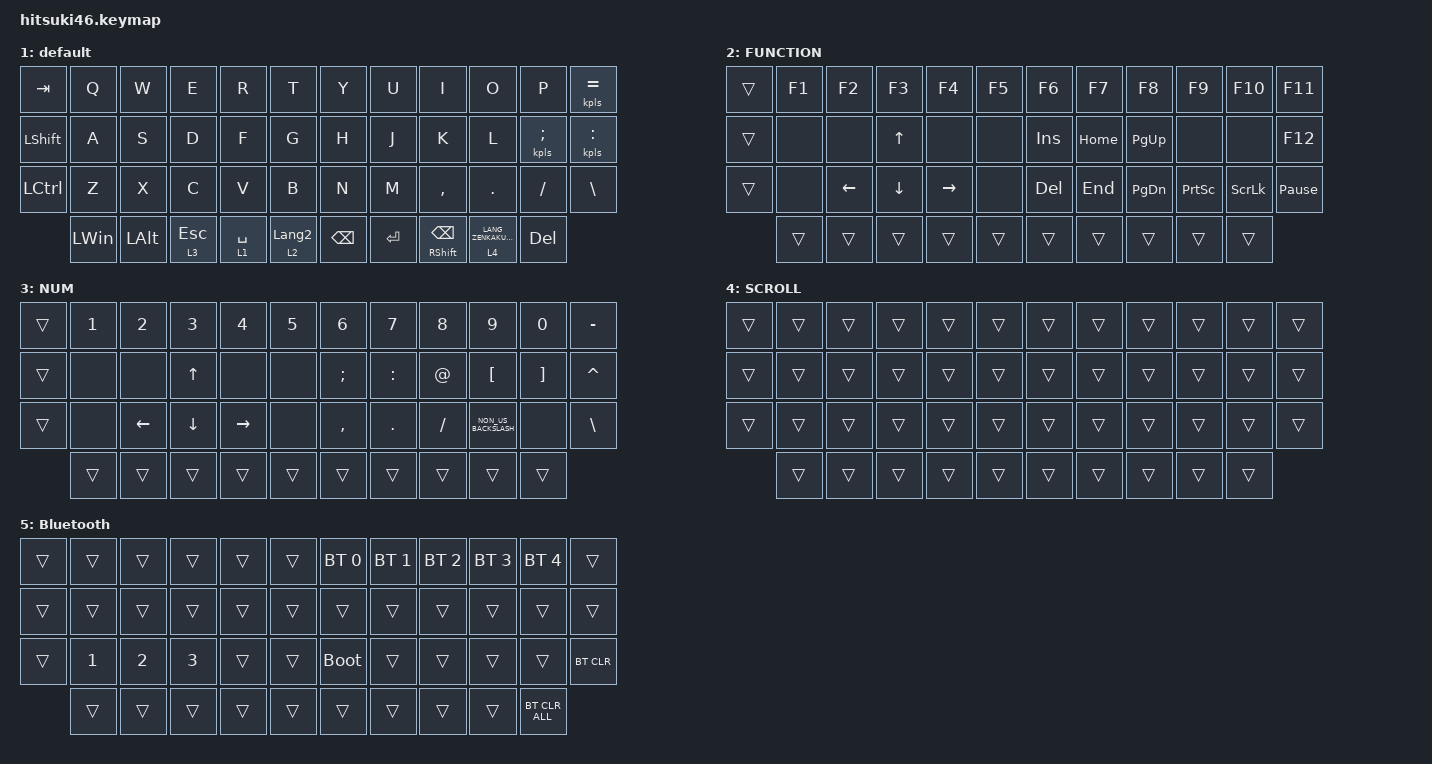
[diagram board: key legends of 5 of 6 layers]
#include <behaviors.dtsi>
#include <dt-bindings/zmk/bt.h>
#include <dt-bindings/zmk/keys.h>
#include <layout_shift_kp_override.dtsi>


/ {
    keymap {
        compatible = "zmk,keymap";

        default_layer {
            bindings = <
                &kpls EQUAL    // 通常は = を出力するが、JISレイアウトでは _ (JISレイアウトでの = に対応)を出力する
                &tog_ls        // レイアウトシフトのオン/オフを切り替える
                &tog_ls_on     // レイアウトシフトをオンにする
                &tog_ls_off    // レイアウトシフトをオフにする
            >;
        };
    };
};

/ {
    behaviors {
        // Keep the original key_press behavior for ZMK core components
        original_key_press: original_key_press {
            compatible = "zmk,behavior-key-press";
            #binding-cells = <1>;
            label = "KEY_PRESS";
        };

        // Override the existing &kp behavior to use our custom implementation
        kp: key_press {
            compatible = "zmk,behavior-layout-shift-key-press";
            #binding-cells = <1>;
            label = "LAYOUT_SHIFT_KEY_PRESS";
        };
    };
};

&mt {
    flavor = "balanced";
    quick-tap-ms = <0>;
};

// &trackball {
//     // Note: automouse-layer and scroll-layers are no longer supported in badjeff/zmk-pmw3610-driver
//     // These features should now be configured using layer-based zmk,input-listener in keymap
//     // automouse-layer = <1>;
//     // scroll-layers = <5>;
// };

/ {
    combos {
        compatible = "zmk,combos";

        tab {
            bindings = <&kp TAB>;
            key-positions = <11 12>;
        };

        shift_tab {
            bindings = <&kp LS(TAB)>;
            key-positions = <12 13>;
        };

        muhennkann {
            bindings = <&to_layer_0 INT_MUHENKAN>;
            key-positions = <11 10>;
        };

        double_quotation {
            bindings = <&kp DOUBLE_QUOTES>;
            key-positions = <20 21>;
        };

        eq {
            bindings = <&kp EQUAL>;
            key-positions = <24 25>;
        };
    };

    macros {
        to_layer_0: to_layer_0 {
            compatible = "zmk,behavior-macro-one-param";
            #binding-cells = <1>;
            bindings = <&to 0 &macro_param_1to1 &kp MACRO_PLACEHOLDER>;
            label = "TO_LAYER_0";
        };
    };

    behaviors {
        lt_to_layer_0: lt_to_layer_0 {
            compatible = "zmk,behavior-hold-tap";
            label = "LAYER_TAP_TO_0";
            bindings = <&mo>, <&to_layer_0>;

            #binding-cells = <2>;
            tapping-term-ms = <200>;
        };
    };

    keymap {
        compatible = "zmk,keymap";

        default {
            bindings = <
&kp TAB     &kp Q         &kp W         &kp E      &kp R        &kp T             &kp Y          &kp U      &kp I                 &kp O                      &kp P            &kpls EQUAL
&kp LSHIFT  &kp A         &kp S         &kp D      &kp F        &kp G             &kp H          &kp J      &kp K                 &kp L                      &kpls SEMICOLON  &kpls COLON
&kp LCTRL   &kp Z         &kp X         &kp C      &kp V        &kp B             &kp N          &kp M      &kp COMMA             &kp PERIOD                 &kp SLASH        &kp BACKSLASH
            &kp LEFT_WIN  &kp LEFT_ALT  &lt 3 ESC  &lt 1 SPACE  &lt 2 LANGUAGE_2  &kp BACKSPACE  &kp ENTER  &mt RSHIFT BACKSPACE  &lt 4 LANG_ZENKAKUHANKAKU  &kp DELETE
            >;
        };

        FUNCTION {
            bindings = <
&trans  &kp F1  &kp F2          &kp F3          &kp F4           &kp F5  &kp F6      &kp F7    &kp F8         &kp F9           &kp F10         &kp F11
&trans  &none   &none           &kp UP_ARROW    &none            &none   &kp INSERT  &kp HOME  &kp PAGE_UP    &none            &none           &kp F12
&trans  &none   &kp LEFT_ARROW  &kp DOWN_ARROW  &kp RIGHT_ARROW  &none   &kp DELETE  &kp END   &kp PAGE_DOWN  &kp PRINTSCREEN  &kp SCROLLLOCK  &kp PAUSE_BREAK
        &trans  &trans          &trans          &trans           &trans  &trans      &trans    &trans         &trans           &trans
            >;
        };

        NUM {
            bindings = <
&trans  &kp N1  &kp N2          &kp N3          &kp N4           &kp N5  &kp N6         &kp N7      &kp N8       &kp N9                &kp N0             &kp MINUS
&trans  &none   &none           &kp UP_ARROW    &none            &none   &kp SEMICOLON  &kp COLON   &kp AT_SIGN  &kp LEFT_BRACKET      &kp RIGHT_BRACKET  &kp CARET
&trans  &none   &kp LEFT_ARROW  &kp DOWN_ARROW  &kp RIGHT_ARROW  &none   &kp COMMA      &kp PERIOD  &kp SLASH    &kp NON_US_BACKSLASH  &none              &kp BACKSLASH
        &trans  &trans          &trans          &trans           &trans  &trans         &trans      &trans       &trans                &trans
            >;
        };

        SCROLL {
            bindings = <
&trans  &trans  &trans  &trans  &trans  &trans  &trans  &trans  &trans  &trans  &trans  &trans
&trans  &trans  &trans  &trans  &trans  &trans  &trans  &trans  &trans  &trans  &trans  &trans
&trans  &trans  &trans  &trans  &trans  &trans  &trans  &trans  &trans  &trans  &trans  &trans
        &trans  &trans  &trans  &trans  &trans  &trans  &trans  &trans  &trans  &trans
            >;
        };

        Bluetooth {
            bindings = <
&trans  &trans        &trans        &trans        &trans  &trans  &bt BT_SEL 0  &bt BT_SEL 1  &bt BT_SEL 2  &bt BT_SEL 3  &bt BT_SEL 4    &trans
&trans  &trans        &trans        &trans        &trans  &trans  &trans        &trans        &trans        &trans        &trans          &trans
&trans  &kp NUMBER_1  &kp NUMBER_2  &kp NUMBER_3  &trans  &trans  &bootloader   &trans        &trans        &trans        &trans          &bt BT_CLR
        &trans        &trans        &trans        &trans  &trans  &trans        &trans        &trans        &trans        &bt BT_CLR_ALL
            >;
        };
    };
};
